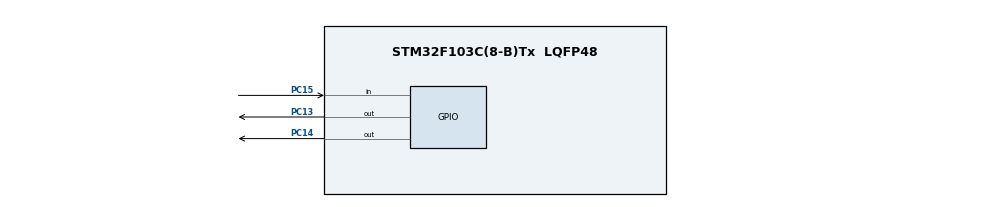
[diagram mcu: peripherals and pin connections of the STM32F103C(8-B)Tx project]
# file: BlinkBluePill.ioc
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Mcu.Family=STM32F1
Mcu.Name=STM32F103C(8-B)Tx
Mcu.Package=LQFP48
NVIC.PriorityGroup=NVIC_PRIORITYGROUP_4
PA13.Mode=Serial_Wire
PA13.Signal=SYS_JTMS-SWDIO
PA14.Mode=Serial_Wire
PA14.Signal=SYS_JTCK-SWCLK
PC13-TAMPER-RTC.Signal=GPIO_Output
PC14-OSC32_IN.Signal=GPIO_Output
PC15-OSC32_OUT.Signal=GPIO_Input
ProjectManager.HeapSize=0x200
ProjectManager.StackSize=0x400
ProjectManager.TargetToolchain=MDK-ARM V5.32
RCC.APB1Freq_Value=8000000
RCC.APB2Freq_Value=8000000
board=custom

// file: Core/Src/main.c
/* USER CODE BEGIN Header */
/**
  ******************************************************************************
  * @file           : main.c
  * @brief          : Main program body
  ******************************************************************************
  * @attention
  *
  * Copyright (c) 2024 STMicroelectronics.
  * All rights reserved.
  *
  * This software is licensed under terms that can be found in the LICENSE file
  * in the root directory of this software component.
  * If no LICENSE file comes with this software, it is provided AS-IS.
  *
  ******************************************************************************
  */
/* USER CODE END Header */
#include "main.h"

/* USER CODE BEGIN Includes */
#include "app_gpio_init.h"
#include "app_lcd.h"
/* USER CODE END Includes */

/* USER CODE BEGIN PTD */
#define  DISP_7SEG			GPIO_PIN_0 | GPIO_PIN_1 | GPIO_PIN_2 | GPIO_PIN_3 | GPIO_PIN_4 | GPIO_PIN_5 | GPIO_PIN_6 | GPIO_PIN_7
#define  SEG_A					GPIO_PIN_0
#define  SEG_B					GPIO_PIN_1
#define  SEG_C					GPIO_PIN_2
#define  SEG_D					GPIO_PIN_3
#define  SEG_E					GPIO_PIN_4
#define  SEG_F					GPIO_PIN_5
#define  SEG_G					GPIO_PIN_6
#define  SEG_PT					GPIO_PIN_7
/* Lcd control defines */
#define  RS_DEF					GPIO_PIN_8
#define  RW_DEF					GPIO_PIN_9
#define  EN_DEF					GPIO_PIN_10
/* Lcd data lines defines */
#define  D0_DEF					GPIO_PIN_0
#define  D1_DEF					GPIO_PIN_1
#define  D2_DEF					GPIO_PIN_2
#define  D3_DEF					GPIO_PIN_3
#define  D4_DEF					GPIO_PIN_4
#define  D5_DEF					GPIO_PIN_5
#define  D6_DEF					GPIO_PIN_6
#define  D7_DEF					GPIO_PIN_7
/* USER CODE END PTD */

void SystemClock_Config(void);
/* USER CODE BEGIN PFP */
static void USR_Selchar_7seg(uint8_t digit);
static void APP1();
static void APP2();
static void APP3();
static void APP4();
static void APP5();
/* USER CODE END PFP */

int main(void)
{

  /* MCU Configuration--------------------------------------------------------*/

  /* Reset of all peripherals, Initializes the Flash interface and the Systick. */
  HAL_Init();

  /* Configure the system clock */
  SystemClock_Config();

  /* USER CODE BEGIN 2 */
	// APP1();
	// APP2();
	// APP3();
	// APP4();
   APP5();
	/* USER CODE END 2 */
}

void SystemClock_Config(void)
{
  RCC_OscInitTypeDef RCC_OscInitStruct = {0};
  RCC_ClkInitTypeDef RCC_ClkInitStruct = {0};

  /** Initializes the RCC Oscillators according to the specified parameters
  * in the RCC_OscInitTypeDef structure.
  */
  RCC_OscInitStruct.OscillatorType = RCC_OSCILLATORTYPE_HSI;
  RCC_OscInitStruct.HSIState = RCC_HSI_ON;
  RCC_OscInitStruct.HSICalibrationValue = RCC_HSICALIBRATION_DEFAULT;
  RCC_OscInitStruct.PLL.PLLState = RCC_PLL_NONE;
  if (HAL_RCC_OscConfig(&RCC_OscInitStruct) != HAL_OK)
  {
    Error_Handler();
  }

  /** Initializes the CPU, AHB and APB buses clocks
  */
  RCC_ClkInitStruct.ClockType = RCC_CLOCKTYPE_HCLK|RCC_CLOCKTYPE_SYSCLK
                              |RCC_CLOCKTYPE_PCLK1|RCC_CLOCKTYPE_PCLK2;
  RCC_ClkInitStruct.SYSCLKSource = RCC_SYSCLKSOURCE_HSI;
  RCC_ClkInitStruct.AHBCLKDivider = RCC_SYSCLK_DIV1;
  RCC_ClkInitStruct.APB1CLKDivider = RCC_HCLK_DIV1;
  RCC_ClkInitStruct.APB2CLKDivider = RCC_HCLK_DIV1;

  if (HAL_RCC_ClockConfig(&RCC_ClkInitStruct, FLASH_LATENCY_0) != HAL_OK)
  {
    Error_Handler();
  }
}

/**
  * @brief Function to show numbers and chars on a 7 segments display
  * @param None
  * @retval None
  */
static void USR_Selchar_7seg(uint8_t digit)
{
	switch(digit)
	{
		case 0:
			HAL_GPIO_WritePin(GPIOA, SEG_G | SEG_PT, GPIO_PIN_SET);
			HAL_GPIO_WritePin(GPIOA, SEG_A | SEG_B | SEG_C | SEG_D | SEG_E | SEG_F, GPIO_PIN_RESET);
			break;
		case 1:
			HAL_GPIO_WritePin(GPIOA, SEG_A | SEG_D | SEG_E | SEG_F | SEG_G | SEG_PT, GPIO_PIN_SET);
			HAL_GPIO_WritePin(GPIOA, SEG_B | SEG_C, GPIO_PIN_RESET);
			break;
		case 2:
			HAL_GPIO_WritePin(GPIOA, SEG_C | SEG_F | SEG_PT, GPIO_PIN_SET);
			HAL_GPIO_WritePin(GPIOA, SEG_A | SEG_B | SEG_D | SEG_E | SEG_G, GPIO_PIN_RESET);
			break;
		case 3:
			HAL_GPIO_WritePin(GPIOA, SEG_E | SEG_F | SEG_PT, GPIO_PIN_SET);
			HAL_GPIO_WritePin(GPIOA, SEG_A | SEG_B | SEG_C | SEG_D | SEG_G, GPIO_PIN_RESET);
			break;
		case 4:
			HAL_GPIO_WritePin(GPIOA, SEG_A | SEG_D | SEG_E | SEG_PT, GPIO_PIN_SET);
			HAL_GPIO_WritePin(GPIOA, SEG_B | SEG_C | SEG_F | SEG_G, GPIO_PIN_RESET);
			break;
		case 5:
			HAL_GPIO_WritePin(GPIOA, SEG_B | SEG_E | SEG_PT, GPIO_PIN_SET);
			HAL_GPIO_WritePin(GPIOA, SEG_A | SEG_C | SEG_D | SEG_F | SEG_G, GPIO_PIN_RESET);
			break;
		case 6:
			HAL_GPIO_WritePin(GPIOA, SEG_B | SEG_PT, GPIO_PIN_SET);
			HAL_GPIO_WritePin(GPIOA, SEG_A | SEG_C | SEG_D | SEG_E | SEG_F | SEG_G, GPIO_PIN_RESET);
			break;
		case 7:
			HAL_GPIO_WritePin(GPIOA, SEG_D | SEG_E | SEG_F | SEG_G | SEG_PT, GPIO_PIN_SET);
			HAL_GPIO_WritePin(GPIOA, SEG_A | SEG_B | SEG_C, GPIO_PIN_RESET);
			break;
		case 8:
			HAL_GPIO_WritePin(GPIOA, SEG_PT, GPIO_PIN_SET);
			HAL_GPIO_WritePin(GPIOA, SEG_A | SEG_B | SEG_C | SEG_D | SEG_E | SEG_F | SEG_G, GPIO_PIN_RESET);
			break;
		case 9:
			HAL_GPIO_WritePin(GPIOA, SEG_E | SEG_PT, GPIO_PIN_SET);
			HAL_GPIO_WritePin(GPIOA, SEG_A | SEG_B | SEG_C | SEG_D | SEG_F | SEG_G, GPIO_PIN_RESET);
			break;
		case 10:
			HAL_GPIO_WritePin(GPIOA, SEG_D | SEG_PT, GPIO_PIN_SET);
			HAL_GPIO_WritePin(GPIOA, SEG_A | SEG_B | SEG_C | SEG_E | SEG_F | SEG_G, GPIO_PIN_RESET);
			break;
		case 12:
			HAL_GPIO_WritePin(GPIOA, SEG_B | SEG_C | SEG_G | SEG_PT, GPIO_PIN_SET);
			HAL_GPIO_WritePin(GPIOA, SEG_A | SEG_D | SEG_E | SEG_F, GPIO_PIN_RESET);
			break;
		default:
			HAL_GPIO_WritePin(GPIOA, DISP_7SEG, GPIO_PIN_SET);
	}

}

/**
  * @brief App for practice pin outputs and inputs, when push the button on portA pin 0 the values on portC pin13 and pin14 toogle values
  * @param None
  * @retval None
  */
static void APP1(){
	USR_GPIO_Init();
	while(1)
	{

		HAL_GPIO_WritePin(GPIOC, GPIO_PIN_13, 1);
		HAL_Delay(500);
		HAL_GPIO_WritePin(GPIOC, GPIO_PIN_13, 0);
		HAL_Delay(500);
		/* App1
		if(HAL_GPIO_ReadPin(GPIOA, GPIO_PIN_0))
		{
			HAL_Delay(5);
			HAL_GPIO_TogglePin(GPIOC, GPIO_PIN_13|GPIO_PIN_14);
		}
		*/
	}
}

/**
  * @brief Counter up / down from 0 - 9 showing in 7 segments display
  * @param None
  * @retval None
  */
static void APP2(){
	/* Init app2 */
	uint8_t counter = 0;
	USR_GPIO_7Seg_Init(GPIOA, GPIO_PIN_0, GPIO_PIN_1, GPIO_PIN_2, GPIO_PIN_3, GPIO_PIN_4, GPIO_PIN_5, GPIO_PIN_6, GPIO_PIN_7);
	USR_GPIO_Pushes_init(GPIOB, GPIO_PIN_3, GPIO_PIN_4);
	while(1)
	{

		/* App2 */
		USR_Selchar_7seg(counter);
		if(HAL_GPIO_ReadPin(GPIOB, GPIO_PIN_3))
		{
			HAL_Delay(200);
			if(counter >= 0 && counter < 9){
				counter++;
			}
			else {
				counter = 0;
			}
		}
		else if(HAL_GPIO_ReadPin(GPIOB, GPIO_PIN_4))
		{
			HAL_Delay(200);
			if(counter > 0 && counter <= 9){
				counter--;
			}
			else {
				counter = 9;
			}
		}

		/*
		HAL_Delay(1000);
		if(counter < 10)
		{
			counter++;
		}
		else
		{
			counter = 0;
		}
		*/

	}
}

/**
  * @brief Trying 4 x 4 matrix keyboard showing in 7 segments display the key pushed
  * @param None
  * @retval None
	* @note
  */
static void APP3(){

	USR_GPIO_4x4Matrix_init(GPIOB, GPIO_PIN_12, GPIO_PIN_13, GPIO_PIN_14, GPIO_PIN_15, GPIO_PIN_3, GPIO_PIN_4, GPIO_PIN_5, GPIO_PIN_6);
	USR_GPIO_7Seg_Init(GPIOA, GPIO_PIN_0, GPIO_PIN_1, GPIO_PIN_2, GPIO_PIN_3, GPIO_PIN_4, GPIO_PIN_5, GPIO_PIN_6, GPIO_PIN_7);
	uint8_t button = 0;
	USR_Selchar_7seg(button);

	while(1){
		/* First column */
		HAL_GPIO_WritePin(GPIOB, GPIO_PIN_12, GPIO_PIN_SET);
		if(HAL_GPIO_ReadPin(GPIOB, GPIO_PIN_3) == 1){
			USR_Selchar_7seg(1);
		} else {
			if(HAL_GPIO_ReadPin(GPIOB, GPIO_PIN_4) == 1){
				USR_Selchar_7seg(4);
			} else {
				if(HAL_GPIO_ReadPin(GPIOB, GPIO_PIN_5) == 1){
					USR_Selchar_7seg(7);
				} else {
					if(HAL_GPIO_ReadPin(GPIOB, GPIO_PIN_6) == 1){
						USR_Selchar_7seg(16);
					}
				}
			}
		}
		/* Second column */
		HAL_GPIO_WritePin(GPIOB, GPIO_PIN_12, GPIO_PIN_RESET);
		HAL_GPIO_WritePin(GPIOB, GPIO_PIN_13, GPIO_PIN_SET);
		if(HAL_GPIO_ReadPin(GPIOB, GPIO_PIN_3) == 1){
			USR_Selchar_7seg(2);
		} else {
			if(HAL_GPIO_ReadPin(GPIOB, GPIO_PIN_4) == 1){
				USR_Selchar_7seg(5);
			} else {
				if(HAL_GPIO_ReadPin(GPIOB, GPIO_PIN_5) == 1){
					USR_Selchar_7seg(8);
				} else {
					if(HAL_GPIO_ReadPin(GPIOB, GPIO_PIN_6) == 1){
						USR_Selchar_7seg(0);
					}
				}
			}
		}
		/* Tirth column */
		HAL_GPIO_WritePin(GPIOB, GPIO_PIN_13, GPIO_PIN_RESET);
		HAL_GPIO_WritePin(GPIOB, GPIO_PIN_14, GPIO_PIN_SET);
		if(HAL_GPIO_ReadPin(GPIOB, GPIO_PIN_3) == 1){
			USR_Selchar_7seg(3);
		} else {
			if(HAL_GPIO_ReadPin(GPIOB, GPIO_PIN_4) == 1){
				USR_Selchar_7seg(6);
			} else {
				if(HAL_GPIO_ReadPin(GPIOB, GPIO_PIN_5) == 1){
					USR_Selchar_7seg(9);
				} else {
					if(HAL_GPIO_ReadPin(GPIOB, GPIO_PIN_6) == 1){
						USR_Selchar_7seg(16);
					}
				}
			}
		}
		/* Fourth column */
		HAL_GPIO_WritePin(GPIOB, GPIO_PIN_14, GPIO_PIN_RESET);
		HAL_GPIO_WritePin(GPIOB, GPIO_PIN_15, GPIO_PIN_SET);
		if(HAL_GPIO_ReadPin(GPIOB, GPIO_PIN_3) == 1){
			USR_Selchar_7seg(10);
		} else {
			if(HAL_GPIO_ReadPin(GPIOB, GPIO_PIN_4) == 1){
				USR_Selchar_7seg(8);
			} else {
				if(HAL_GPIO_ReadPin(GPIOB, GPIO_PIN_5) == 1){
					USR_Selchar_7seg(12);
				} else {
					if(HAL_GPIO_ReadPin(GPIOB, GPIO_PIN_6) == 1){
						USR_Selchar_7seg(0);
					}
				}
			}
		}
		HAL_GPIO_WritePin(GPIOB, GPIO_PIN_15, GPIO_PIN_RESET);

	}

}

/**
  * @brief LCD
  * @param None
  * @retval None
	* @note
  */
static void APP4(){

	lcd_initialize_pins(GPIOA,RS_DEF,RW_DEF,EN_DEF,D0_DEF,D1_DEF,D2_DEF,D3_DEF,D4_DEF,D5_DEF,D6_DEF,D7_DEF);
	HAL_GPIO_WritePin(GPIOA, D0_DEF|D1_DEF|D2_DEF|D3_DEF|D4_DEF|D5_DEF|D6_DEF|D7_DEF|RS_DEF|RW_DEF|EN_DEF, GPIO_PIN_RESET);
	lcd_initialize(GPIOA,RS_DEF,RW_DEF,EN_DEF,D0_DEF,D1_DEF,D2_DEF,D3_DEF,D4_DEF,D5_DEF,D6_DEF,D7_DEF);

	while(1){
		lcd_cmd(GPIOA, 0x80, RS_DEF,RW_DEF,EN_DEF,D0_DEF,D1_DEF,D2_DEF,D3_DEF,D4_DEF,D5_DEF,D6_DEF,D7_DEF);
		//HAL_Delay(500);
		lcd_data(GPIOA, 'A', RS_DEF,RW_DEF,EN_DEF,D0_DEF,D1_DEF,D2_DEF,D3_DEF,D4_DEF,D5_DEF,D6_DEF,D7_DEF);
		//HAL_Delay(500);
		lcd_data(GPIOA, 0xFF, RS_DEF,RW_DEF,EN_DEF,D0_DEF,D1_DEF,D2_DEF,D3_DEF,D4_DEF,D5_DEF,D6_DEF,D7_DEF);
		//HAL_Delay(500);
		//lcd_data(GPIOA, 'B', RS, RW, EN, D0, D1, D2, D3, D4, D5, D6, D7);
		//HAL_Delay(500);
		//lcd_data(GPIOA, 'C', RS, RW, EN, D0, D1, D2, D3, D4, D5, D6, D7);
		//HAL_Delay(500);
	}

}

/**
  * @brief LCD
  * @param None
  * @retval None
	* @note
  */
static void APP5(){

	LCD_8BitMode_TypeDef lcd1 = {
		.RS = RS_DEF,
		.RW = RW_DEF,
		.EN = EN_DEF,
		.D0 = D0_DEF,
		.D1 = D1_DEF,
		.D2 = D2_DEF,
		.D3 = D3_DEF,
		.D4 = D4_DEF,
		.D5 = D5_DEF,
		.D6 = D6_DEF,
		.D7 = D7_DEF,
		.GPIOx = GPIOA
	};

	LCD_Initialize_Port(&lcd1);
	HAL_GPIO_WritePin(GPIOA, D0_DEF|D1_DEF|D2_DEF|D3_DEF|D4_DEF|D5_DEF|D6_DEF|D7_DEF|RS_DEF|RW_DEF|EN_DEF, GPIO_PIN_RESET);
	LCD_Initialize(&lcd1);

	while(1){

		LCD_Cmd(0x80, &lcd1);
		LCD_String("->  PRIMERA   <-", 16, &lcd1);
		LCD_Cmd(0xC0, &lcd1);
		LCD_String("->  SEGUNDA   <-", 16, &lcd1);

	}

}
static void MX_GPIO_Init(void)
{
  GPIO_InitTypeDef GPIO_InitStruct = {0};

  /* GPIO Ports Clock Enable */
  __HAL_RCC_GPIOC_CLK_ENABLE();
  __HAL_RCC_GPIOA_CLK_ENABLE();

  /*Configure GPIO pin Output Level */
  HAL_GPIO_WritePin(GPIOC, GPIO_PIN_13|GPIO_PIN_14, GPIO_PIN_RESET);

  /*Configure GPIO pins : PC13 PC14 */
  GPIO_InitStruct.Pin = GPIO_PIN_13|GPIO_PIN_14;
  GPIO_InitStruct.Mode = GPIO_MODE_OUTPUT_PP;
  GPIO_InitStruct.Pull = GPIO_NOPULL;
  GPIO_InitStruct.Speed = GPIO_SPEED_FREQ_LOW;
  HAL_GPIO_Init(GPIOC, &GPIO_InitStruct);

  /*Configure GPIO pin : PC15 */
  GPIO_InitStruct.Pin = GPIO_PIN_15;
  GPIO_InitStruct.Mode = GPIO_MODE_INPUT;
  GPIO_InitStruct.Pull = GPIO_NOPULL;
  HAL_GPIO_Init(GPIOC, &GPIO_InitStruct);

}

/* USER CODE BEGIN 4 */
// static void
/* USER CODE END 4 */

void Error_Handler(void)
{
  __disable_irq();
  while (1)
  {
  }
}
